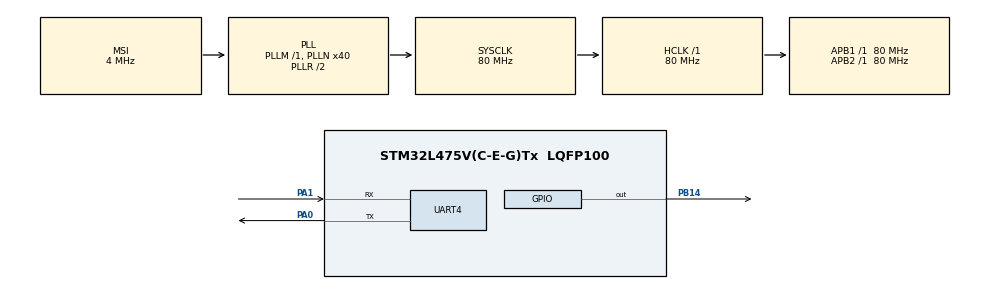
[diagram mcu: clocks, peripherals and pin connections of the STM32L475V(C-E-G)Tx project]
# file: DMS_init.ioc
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Mcu.Family=STM32L4
Mcu.Name=STM32L475V(C-E-G)Tx
Mcu.Package=LQFP100
NVIC.PriorityGroup=NVIC_PRIORITYGROUP_4
NVIC.UART4_IRQn=true\:0\:0\:false\:false\:true\:true\:true\:true
PA0.Mode=Asynchronous
PA0.Signal=UART4_TX
PA1.Mode=Asynchronous
PA1.Signal=UART4_RX
PA13\ (JTMS-SWDIO).Mode=Serial_Wire
PA13\ (JTMS-SWDIO).Signal=SYS_JTMS-SWDIO
PA14\ (JTCK-SWCLK).Mode=Serial_Wire
PA14\ (JTCK-SWCLK).Signal=SYS_JTCK-SWCLK
PB14.Signal=GPIO_Output
ProjectManager.HeapSize=0x200
ProjectManager.StackSize=0x400
ProjectManager.TargetToolchain=STM32CubeIDE
RCC.ADCFreq_Value=48000000
RCC.AHBFreq_Value=80000000
RCC.APB1Freq_Value=80000000
RCC.APB1TimFreq_Value=80000000
RCC.APB2Freq_Value=80000000
RCC.APB2TimFreq_Value=80000000
RCC.CortexFreq_Value=80000000
RCC.HCLKFreq_Value=80000000
RCC.HSE_VALUE=8000000
RCC.HSI_VALUE=16000000
RCC.LSE_VALUE=32768
RCC.MSI_VALUE=4000000
RCC.PLLN=40
RCC.PLLSAI1N=24
RCC.SYSCLKFreq_VALUE=80000000
RCC.SYSCLKSource=RCC_SYSCLKSOURCE_PLLCLK
RCC.USBFreq_Value=48000000
RCC.VCOOutputFreq_Value=160000000
board=B-L475E-IOT01A2

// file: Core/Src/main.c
/* USER CODE BEGIN Header */
/**
  ******************************************************************************
  * @file           : main.c
  * @brief          : Main program body
  ******************************************************************************
  * @attention
  *
  * Copyright (c) 2026 STMicroelectronics.
  * All rights reserved.
  *
  * This software is licensed under terms that can be found in the LICENSE file
  * in the root directory of this software component.
  * If no LICENSE file comes with this software, it is provided AS-IS.
  *
  ******************************************************************************
  */
/* USER CODE END Header */
#include "main.h"
#include "usart.h"
#include "gpio.h"

/* USER CODE BEGIN PV */

// 전역변수 선언 위치긴 한데.. 전역변수 쓰면 안되는걸로 알고있는데 일단 구현이 먼저니까 진행
uint8_t rx_byte = 0;
uint8_t rx_buf[4];
uint8_t rx_idx = 0;
uint8_t rx_state = 0;
volatile uint8_t driver_state = 0;

/* USER CODE END PV */

void SystemClock_Config(void); // 80 MHz 클럭 세팅

int main(void)
{

  /* MCU Configuration--------------------------------------------------------*/

  /* Reset of all peripherals, Initializes the Flash interface and the Systick. */
  HAL_Init();

  /* Configure the system clock */
  SystemClock_Config();

  /* Initialize all configured peripherals */
  MX_GPIO_Init(); // PB14(LED2) GPIO_Output 초기화
  MX_UART4_Init(); // PA0, PA1, 115200 8N1, 인터럽트 모드
  /* USER CODE BEGIN 2 */

  // 초기화 후 실행할 코드는 여기( UART 수신 시작 코드)
  HAL_UART_Receive_IT(&huart4, &rx_byte, 1); // UART의 수신 시작점.
  // UART4에서 1바이트가 오면 rx_byte에 넣고 인터럽트 발생시 켜줘. 라는 예약
  // 이걸 호출한 이후부터  UART4에 데이터가 오면 자동으로 HAL_UART_RxCpltCallback이 불림.
  // 한 번만 호출하면 되고. 이후에는 재호출로 이어지는 구조.

  /* USER CODE END 2 */

  /* Infinite loop */
  /* USER CODE BEGIN WHILE */
  while (1)
  {
	  //메인 루프(LED 제어)
	  // driver_state에 따라 LED 제어
	  // State = 0 : LED OFF
	  // State = 1 : LED 토글(HAL_Delay로 깜빡임)
	  // State = 2 : LED ON

	  switch(driver_state){
	  	  case 0 :
	  		  // LED OFF
	  		  HAL_GPIO_WritePin(GPIOB, GPIO_PIN_14, GPIO_PIN_RESET);
	  		  break;
	  	  case 1:
	  		  // LED Toggle
	  		  HAL_GPIO_TogglePin(GPIOB, GPIO_PIN_14);
	  	      HAL_Delay(500);
	  		  break;
	  	  case 2:
	  		  // LED ON
	  		  HAL_GPIO_WritePin(GPIOB, GPIO_PIN_14, GPIO_PIN_SET);

	  		  break;
	  	  default:
	  		  // 비움
	  		  break;
	  }

    /* USER CODE END WHILE */

  }
}

void SystemClock_Config(void)
{
  RCC_OscInitTypeDef RCC_OscInitStruct = {0};
  RCC_ClkInitTypeDef RCC_ClkInitStruct = {0};

  /** Configure the main internal regulator output voltage
  */
  if (HAL_PWREx_ControlVoltageScaling(PWR_REGULATOR_VOLTAGE_SCALE1) != HAL_OK)
  {
    Error_Handler();
  }

  /** Initializes the RCC Oscillators according to the specified parameters
  * in the RCC_OscInitTypeDef structure.
  */
  RCC_OscInitStruct.OscillatorType = RCC_OSCILLATORTYPE_MSI;
  RCC_OscInitStruct.MSIState = RCC_MSI_ON;
  RCC_OscInitStruct.MSICalibrationValue = 0;
  RCC_OscInitStruct.MSIClockRange = RCC_MSIRANGE_6;
  RCC_OscInitStruct.PLL.PLLState = RCC_PLL_ON;
  RCC_OscInitStruct.PLL.PLLSource = RCC_PLLSOURCE_MSI;
  RCC_OscInitStruct.PLL.PLLM = 1;
  RCC_OscInitStruct.PLL.PLLN = 40;
  RCC_OscInitStruct.PLL.PLLP = RCC_PLLP_DIV7;
  RCC_OscInitStruct.PLL.PLLQ = RCC_PLLQ_DIV2;
  RCC_OscInitStruct.PLL.PLLR = RCC_PLLR_DIV2;
  if (HAL_RCC_OscConfig(&RCC_OscInitStruct) != HAL_OK)
  {
    Error_Handler();
  }

  /** Initializes the CPU, AHB and APB buses clocks
  */
  RCC_ClkInitStruct.ClockType = RCC_CLOCKTYPE_HCLK|RCC_CLOCKTYPE_SYSCLK
                              |RCC_CLOCKTYPE_PCLK1|RCC_CLOCKTYPE_PCLK2;
  RCC_ClkInitStruct.SYSCLKSource = RCC_SYSCLKSOURCE_PLLCLK;
  RCC_ClkInitStruct.AHBCLKDivider = RCC_SYSCLK_DIV1;
  RCC_ClkInitStruct.APB1CLKDivider = RCC_HCLK_DIV1;
  RCC_ClkInitStruct.APB2CLKDivider = RCC_HCLK_DIV1;

  if (HAL_RCC_ClockConfig(&RCC_ClkInitStruct, FLASH_LATENCY_4) != HAL_OK)
  {
    Error_Handler();
  }
}

/* USER CODE BEGIN 4 */

// 인터럽트 콜백 함수 작성
// UART가 여러개일 수 있으니 UART4에서 온 것만 처리하고,
// UART4로 1바이트 수신 완료될 때마다 HAL이 자동으로 호출된다.
void HAL_UART_RxCpltCallback(UART_HandleTypeDef *huart)
{
	if(huart->Instance == UART4)
	{
		// 상태머신으로 프레임 파싱
		// 완성되면 driver_state 업데이트 할것
		if(rx_state == 0)
		{
			// 1. rx_byte가 0xAA 인지 확인
			// 2. 맞다면 rx_state를 1로 변경, rx_idx를 0으로 초기화

			if(rx_byte == 0xAA)
			{
				rx_state = 1;
				rx_idx = 0;
			}
		}
		else if(rx_state ==1)
		{
			// 1. rx_buf[rx_idx]에 rx_byte 저장 후 rx_idx 1 증가
			// 2. rx_idx가 4가 되었는지 확인 (데이터 4개 다 받았는지)
			// 3. 4개를 다 받았다면:
			//   - CheckSum 계산 및 검증
			//   - 일치하면 driver_state = rx_buf[0]; 업데이트
			//   - 다음 프레임을 위해 rx_state를 0으로 리셋

			rx_buf[rx_idx++] = rx_byte;
			if(rx_idx == 4)
			{
				uint8_t calc = (0xAA + rx_buf[0] + rx_buf[1] + rx_buf[2]) & 0xFF;
				if(calc == rx_buf[3]) driver_state = rx_buf[0];
				rx_state = 0;
			}
		}

		HAL_UART_Receive_IT(huart, &rx_byte, 1); // 다음 바이트 대기
	}
}
/* USER CODE END 4 */

void Error_Handler(void)
{
  __disable_irq();
  while (1)
  {
  }
}
